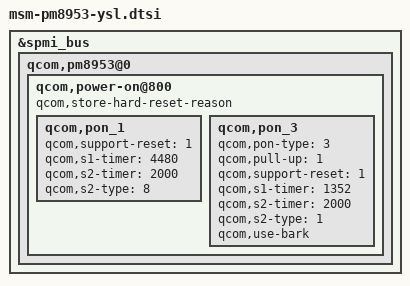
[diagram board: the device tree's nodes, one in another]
/*
 * Copyright (c) 2015-2016, 2018, The Linux Foundation. All rights reserved.
 * Copyright (C) 2019 XiaoMi, Inc.
 *
 * This program is free software; you can redistribute it and/or modify
 * it under the terms of the GNU General Public License version 2 and
 * only version 2 as published by the Free Software Foundation.
 *
 * This program is distributed in the hope that it will be useful,
 * but WITHOUT ANY WARRANTY; without even the implied warranty of
 * MERCHANTABILITY or FITNESS FOR A PARTICULAR PURPOSE.  See the
 * GNU General Public License for more details.
 */

&spmi_bus {
	qcom,pm8953@0 {
		qcom,power-on@800 {
			qcom,store-hard-reset-reason;
			qcom,pon_1 {
				qcom,support-reset = <1>;
				qcom,s1-timer = <4480>;
				qcom,s2-timer = <2000>;
				qcom,s2-type = <8>;
			};
			qcom,pon_3 {
				qcom,pon-type = <3>;
				qcom,pull-up = <1>;
				qcom,support-reset = <1>;
				qcom,s1-timer = <1352>;
				qcom,s2-timer = <2000>;
				qcom,s2-type = <1>;
				qcom,use-bark;
			};
		};
	};
};
